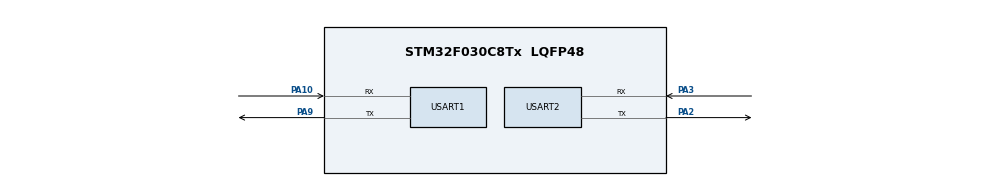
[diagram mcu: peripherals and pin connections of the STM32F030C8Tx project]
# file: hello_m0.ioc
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IWDG.Prescaler=IWDG_PRESCALER_256
Mcu.Family=STM32F0
Mcu.Name=STM32F030C8Tx
Mcu.Package=LQFP48
NVIC.USART1_IRQn=true\:0\:0\:false\:false\:true\:true\:true
NVIC.USART2_IRQn=true\:0\:0\:false\:false\:true\:true\:true
PA10.Mode=Asynchronous
PA10.Signal=USART1_RX
PA2.Mode=Asynchronous
PA2.Signal=USART2_TX
PA3.Mode=Asynchronous
PA3.Signal=USART2_RX
PA9.Mode=Asynchronous
PA9.Signal=USART1_TX
ProjectManager.HeapSize=0x200
ProjectManager.StackSize=0x400
ProjectManager.TargetToolchain=Makefile
USART1.VirtualMode-Asynchronous=VM_ASYNC
USART2.VirtualMode-Asynchronous=VM_ASYNC
VP_CRC_VS_CRC.Mode=CRC_Activate
VP_IWDG_VS_IWDG.Mode=IWDG_Activate
board=custom

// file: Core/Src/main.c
/* USER CODE BEGIN Header */
/**
  ******************************************************************************
  * @file           : main.c
  * @brief          : Main program body
  ******************************************************************************
  * @attention
  *
  * Copyright (c) 2022 STMicroelectronics.
  * All rights reserved.
  *
  * This software is licensed under terms that can be found in the LICENSE file
  * in the root directory of this software component.
  * If no LICENSE file comes with this software, it is provided AS-IS.
  *
  ******************************************************************************
  */
/* USER CODE END Header */

#include "main.h"

/* USER CODE BEGIN Includes */
#include "main_loop.h"

#ifdef USB_ENABLE
#include "usb_device.h"
#endif

/* USER CODE END Includes */

CRC_HandleTypeDef hcrc;

IWDG_HandleTypeDef hiwdg;

UART_HandleTypeDef huart1;
UART_HandleTypeDef huart2;

void SystemClock_Config(void);
static void MX_GPIO_Init(void);
static void MX_CRC_Init(void);
static void MX_IWDG_Init(void);
#if 0
static void MX_USART1_UART_Init(void);
static void MX_USART2_UART_Init(void);
#endif

int main(void)
{

  /* MCU Configuration--------------------------------------------------------*/

  /* Reset of all peripherals, Initializes the Flash interface and the Systick. */
  HAL_Init();

  /* Configure the system clock */
  SystemClock_Config();

  /* Initialize all configured peripherals */
  MX_GPIO_Init();
  MX_CRC_Init();
  MX_IWDG_Init();
  #if 0
  MX_USART1_UART_Init();
  MX_USART2_UART_Init();
  #endif

  /* Infinite loop */
  /* USER CODE BEGIN WHILE */
  main_loop();

  while (1)
  {
    /* USER CODE END WHILE */

  }
}

void SystemClock_Config(void)
{
  RCC_OscInitTypeDef RCC_OscInitStruct = {0};
  RCC_ClkInitTypeDef RCC_ClkInitStruct = {0};
  RCC_PeriphCLKInitTypeDef PeriphClkInit = {0};

  /** Initializes the RCC Oscillators according to the specified parameters
  * in the RCC_OscInitTypeDef structure.
  */
  RCC_OscInitStruct.OscillatorType = RCC_OSCILLATORTYPE_HSI|RCC_OSCILLATORTYPE_LSI;
  RCC_OscInitStruct.HSIState = RCC_HSI_ON;
  RCC_OscInitStruct.HSICalibrationValue = RCC_HSICALIBRATION_DEFAULT;
  RCC_OscInitStruct.LSIState = RCC_LSI_ON;
  RCC_OscInitStruct.PLL.PLLState = RCC_PLL_NONE;
  if (HAL_RCC_OscConfig(&RCC_OscInitStruct) != HAL_OK)
  {
    Error_Handler();
  }
  /** Initializes the CPU, AHB and APB buses clocks
  */
  RCC_ClkInitStruct.ClockType = RCC_CLOCKTYPE_HCLK|RCC_CLOCKTYPE_SYSCLK
                              |RCC_CLOCKTYPE_PCLK1;
  RCC_ClkInitStruct.SYSCLKSource = RCC_SYSCLKSOURCE_HSI;
  RCC_ClkInitStruct.AHBCLKDivider = RCC_SYSCLK_DIV1;
  RCC_ClkInitStruct.APB1CLKDivider = RCC_HCLK_DIV1;

  if (HAL_RCC_ClockConfig(&RCC_ClkInitStruct, FLASH_LATENCY_0) != HAL_OK)
  {
    Error_Handler();
  }
  PeriphClkInit.PeriphClockSelection = RCC_PERIPHCLK_USART1;
  PeriphClkInit.Usart1ClockSelection = RCC_USART1CLKSOURCE_PCLK1;
  if (HAL_RCCEx_PeriphCLKConfig(&PeriphClkInit) != HAL_OK)
  {
    Error_Handler();
  }
}

static void MX_CRC_Init(void)
{

  hcrc.Instance = CRC;
  hcrc.Init.DefaultInitValueUse = DEFAULT_INIT_VALUE_ENABLE;
  hcrc.Init.InputDataInversionMode = CRC_INPUTDATA_INVERSION_NONE;
  hcrc.Init.OutputDataInversionMode = CRC_OUTPUTDATA_INVERSION_DISABLE;
  hcrc.InputDataFormat = CRC_INPUTDATA_FORMAT_BYTES;
  if (HAL_CRC_Init(&hcrc) != HAL_OK)
  {
    Error_Handler();
  }

}

static void MX_IWDG_Init(void)
{

  hiwdg.Instance = IWDG;
  hiwdg.Init.Prescaler = IWDG_PRESCALER_256;
  hiwdg.Init.Window = 4095;
  hiwdg.Init.Reload = 4095;
  if (HAL_IWDG_Init(&hiwdg) != HAL_OK)
  {
    Error_Handler();
  }

}

#if 0
static void MX_USART1_UART_Init(void)
{

  huart1.Instance = USART1;
  huart1.Init.BaudRate = 115200;
  huart1.Init.WordLength = UART_WORDLENGTH_8B;
  huart1.Init.StopBits = UART_STOPBITS_1;
  huart1.Init.Parity = UART_PARITY_NONE;
  huart1.Init.Mode = UART_MODE_TX_RX;
  huart1.Init.HwFlowCtl = UART_HWCONTROL_NONE;
  huart1.Init.OverSampling = UART_OVERSAMPLING_16;
  huart1.Init.OneBitSampling = UART_ONE_BIT_SAMPLE_DISABLE;
  huart1.AdvancedInit.AdvFeatureInit = UART_ADVFEATURE_NO_INIT;
  if (HAL_UART_Init(&huart1) != HAL_OK)
  {
    Error_Handler();
  }

}

static void MX_USART2_UART_Init(void)
{

  huart2.Instance = USART2;
  huart2.Init.BaudRate = 115200;
  huart2.Init.WordLength = UART_WORDLENGTH_8B;
  huart2.Init.StopBits = UART_STOPBITS_1;
  huart2.Init.Parity = UART_PARITY_NONE;
  huart2.Init.Mode = UART_MODE_TX_RX;
  huart2.Init.HwFlowCtl = UART_HWCONTROL_NONE;
  huart2.Init.OverSampling = UART_OVERSAMPLING_16;
  huart2.Init.OneBitSampling = UART_ONE_BIT_SAMPLE_DISABLE;
  huart2.AdvancedInit.AdvFeatureInit = UART_ADVFEATURE_NO_INIT;
  if (HAL_UART_Init(&huart2) != HAL_OK)
  {
    Error_Handler();
  }

}
#endif
static void MX_GPIO_Init(void)
{
	#if (defined STM32L151xB)
		/* GPIO Ports Clock Enable */
		__HAL_RCC_GPIOC_CLK_ENABLE();
		__HAL_RCC_GPIOH_CLK_ENABLE();
		__HAL_RCC_GPIOA_CLK_ENABLE();
		__HAL_RCC_GPIOB_CLK_ENABLE();
	#elif (defined STM32F030x8)
		__HAL_RCC_GPIOA_CLK_ENABLE();
		__HAL_RCC_GPIOB_CLK_ENABLE();
	#else
	#error
	#endif
}

void Error_Handler(void)
{
  /* USER CODE BEGIN Error_Handler_Debug */
  /* User can add his own implementation to report the HAL error return state */
  sysErrorHandler(SYS_ERROR_FROM_MX_MAIN);
  __disable_irq();
  while (1)
  {
  }
  /* USER CODE END Error_Handler_Debug */
}
